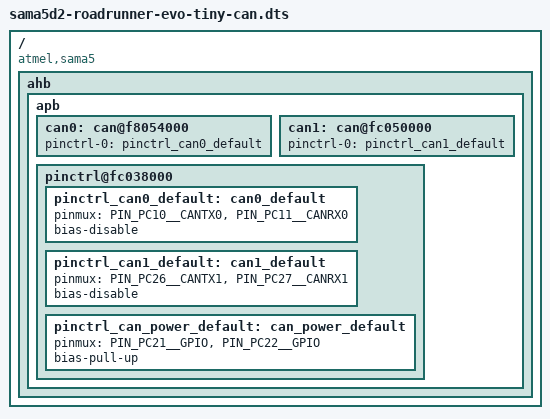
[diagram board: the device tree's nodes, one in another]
/dts-v1/;
/plugin/;

#include "../sama5d2-pinfunc.h"
#include <dt-bindings/gpio/gpio.h>
#include <dt-bindings/mfd/atmel-flexcom.h>

/ {
    fragment@111110 {
        target-path = "/";
        __overlay__ {
            compatible = "atmel,sama5", "atmel,sama5d2", "atmel,sama5d2-evo-tiny-can";
            ahb {
                apb {
                    can0: can@f8054000 {
                        pinctrl-names = "default";
                        pinctrl-0 = <&pinctrl_can0_default>;
                        status = "okay";
                    };
                    can1: can@fc050000 {
                        pinctrl-names = "default";
                        pinctrl-0 = <&pinctrl_can1_default>;
                        status = "okay";
                    };

                    pinctrl@fc038000 {
                        pinctrl_can0_default: can0_default {
                            pinmux = <PIN_PC10__CANTX0>,
                                     <PIN_PC11__CANRX0>;
                            bias-disable;
                        };

                        pinctrl_can1_default: can1_default {
                            pinmux = <PIN_PC26__CANTX1>,
                                     <PIN_PC27__CANRX1>;
                            bias-disable;
                        };

                        pinctrl_can_power_default: can_power_default {
                            pinmux  = <PIN_PC21__GPIO>,
                                      <PIN_PC22__GPIO>;
                            bias-pull-up;
                        };
                    };
                };
            };
        };
    };
};

